VERSION ""

NS_ :

BS_:

BU_: UNKNOWN

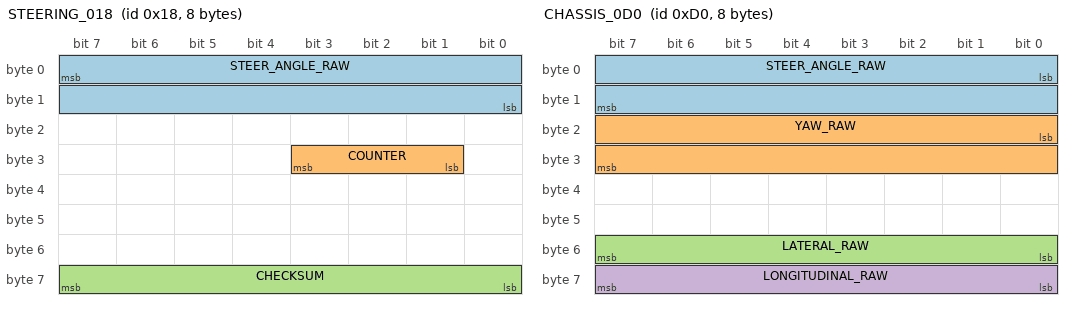
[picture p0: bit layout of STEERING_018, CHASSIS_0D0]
BO_ 24 STEERING_018: 8 UNKNOWN
 SG_ STEER_ANGLE_RAW : 7|16@0- (1,0) [-32768|32767] "raw" UNKNOWN
 SG_ COUNTER : 25|3@1+ (1,0) [0|7] "" UNKNOWN
 SG_ CHECKSUM : 56|8@1+ (1,0) [0|255] "" UNKNOWN

BO_ 208 CHASSIS_0D0: 8 UNKNOWN
 SG_ STEER_ANGLE_RAW : 0|16@1- (1,0) [-32768|32767] "raw" UNKNOWN
 SG_ YAW_RAW : 16|16@1- (1,0) [-32768|32767] "raw" UNKNOWN
 SG_ LATERAL_RAW : 48|8@1- (1,0) [-128|127] "raw" UNKNOWN
 SG_ LONGITUDINAL_RAW : 56|8@1- (1,0) [-128|127] "raw" UNKNOWN

BO_ 209 SPEED_0D1: 4 UNKNOWN
 SG_ VEHICLE_SPEED : 0|16@1+ (0.0563,0) [0|3690] "km/h" UNKNOWN
 SG_ BRAKE_PRESSURE_RAW : 16|8@1+ (1,0) [0|255] "raw" UNKNOWN

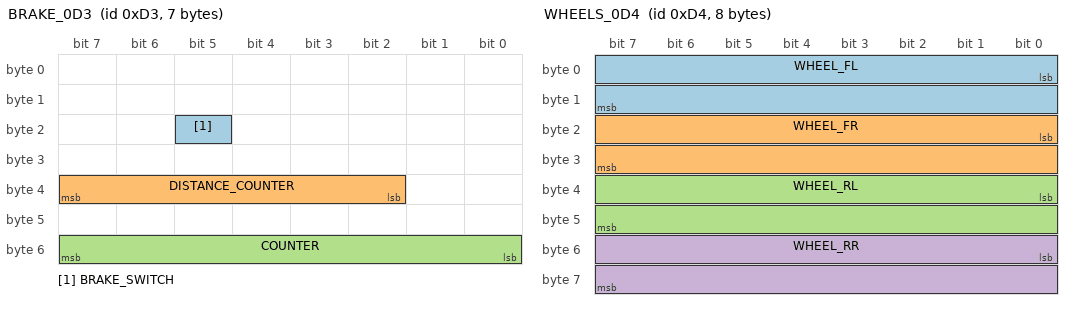
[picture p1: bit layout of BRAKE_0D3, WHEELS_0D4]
BO_ 211 BRAKE_0D3: 7 UNKNOWN
 SG_ BRAKE_SWITCH : 21|1@1+ (1,0) [0|1] "" UNKNOWN
 SG_ DISTANCE_COUNTER : 34|6@1+ (1,0) [0|63] "" UNKNOWN
 SG_ COUNTER : 48|8@1+ (1,0) [0|255] "" UNKNOWN

BO_ 212 WHEELS_0D4: 8 UNKNOWN
 SG_ WHEEL_FL : 0|16@1+ (0.0563,0) [0|3690] "km/h" UNKNOWN
 SG_ WHEEL_FR : 16|16@1+ (0.0563,0) [0|3690] "km/h" UNKNOWN
 SG_ WHEEL_RL : 32|16@1+ (0.0563,0) [0|3690] "km/h" UNKNOWN
 SG_ WHEEL_RR : 48|16@1+ (0.0563,0) [0|3690] "km/h" UNKNOWN

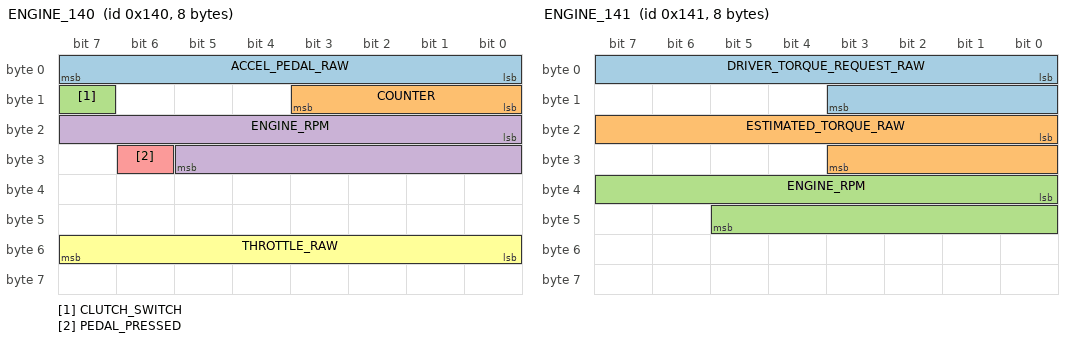
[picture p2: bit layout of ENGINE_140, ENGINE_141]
BO_ 320 ENGINE_140: 8 UNKNOWN
 SG_ ACCEL_PEDAL_RAW : 0|8@1+ (1,0) [0|255] "raw" UNKNOWN
 SG_ COUNTER : 8|4@1+ (1,0) [0|15] "" UNKNOWN
 SG_ CLUTCH_SWITCH : 15|1@1+ (1,0) [0|1] "" UNKNOWN
 SG_ ENGINE_RPM : 16|14@1+ (1,0) [0|16383] "rpm" UNKNOWN
 SG_ PEDAL_PRESSED : 30|1@1+ (1,0) [0|1] "" UNKNOWN
 SG_ THROTTLE_RAW : 48|8@1+ (1,0) [0|255] "raw" UNKNOWN

BO_ 321 ENGINE_141: 8 UNKNOWN
 SG_ DRIVER_TORQUE_REQUEST_RAW : 0|12@1+ (1,0) [0|4095] "raw" UNKNOWN
 SG_ ESTIMATED_TORQUE_RAW : 16|12@1+ (1,0) [0|4095] "raw" UNKNOWN
 SG_ ENGINE_RPM : 32|14@1+ (1,0) [0|16383] "rpm" UNKNOWN

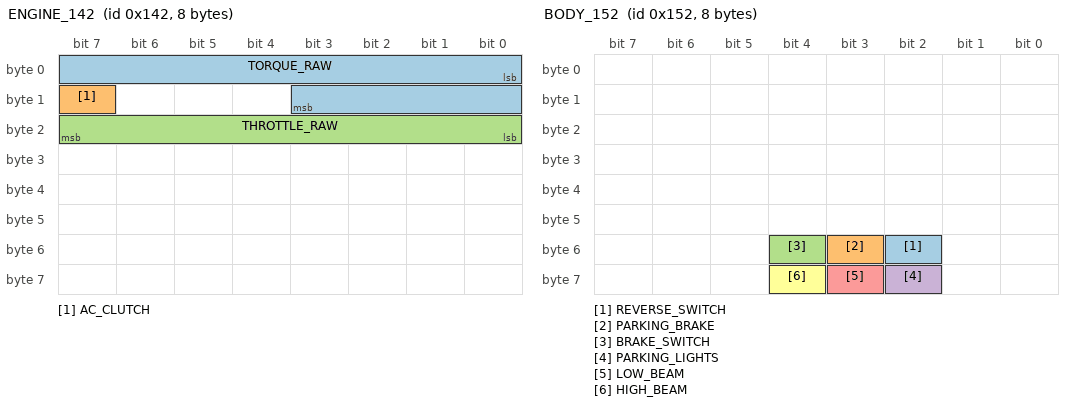
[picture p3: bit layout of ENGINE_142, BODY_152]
BO_ 322 ENGINE_142: 8 UNKNOWN
 SG_ TORQUE_RAW : 0|12@1+ (1,0) [0|4095] "raw" UNKNOWN
 SG_ AC_CLUTCH : 15|1@1+ (1,0) [0|1] "" UNKNOWN
 SG_ THROTTLE_RAW : 16|8@1+ (1,0) [0|255] "raw" UNKNOWN

BO_ 338 BODY_152: 8 UNKNOWN
 SG_ REVERSE_SWITCH : 50|1@1+ (1,0) [0|1] "" UNKNOWN
 SG_ PARKING_BRAKE : 51|1@1+ (1,0) [0|1] "" UNKNOWN
 SG_ BRAKE_SWITCH : 52|1@1+ (1,0) [0|1] "" UNKNOWN
 SG_ PARKING_LIGHTS : 58|1@1+ (1,0) [0|1] "" UNKNOWN
 SG_ LOW_BEAM : 59|1@1+ (1,0) [0|1] "" UNKNOWN
 SG_ HIGH_BEAM : 60|1@1+ (1,0) [0|1] "" UNKNOWN

BO_ 640 STATUS_280: 8 UNKNOWN
 SG_ AC_REQUEST : 0|1@1+ (1,0) [0|1] "" UNKNOWN

BO_ 642 BODY_282: 8 UNKNOWN
 SG_ SEATBELT_UNBUCKLED : 40|1@1+ (1,0) [0|1] "" UNKNOWN

BO_ 644 START_284: 8 UNKNOWN
 SG_ CLUTCH_START_INTERLOCK : 44|1@1+ (1,0) [0|1] "" UNKNOWN

BO_ 864 ENGINE_360: 8 UNKNOWN
 SG_ OIL_TEMP : 16|8@1+ (1,-40) [-40|215] "C" UNKNOWN
 SG_ COOLANT_TEMP : 24|8@1+ (1,-40) [-40|215] "C" UNKNOWN

BO_ 865 ENGINE_361: 8 UNKNOWN
 SG_ ENGINE_RUNNING_LIKELY : 13|1@1+ (1,0) [0|1] "" UNKNOWN

BO_ 884 BODY_374: 8 UNKNOWN
 SG_ DOOR_OPEN : 24|1@1+ (1,0) [0|1] "" UNKNOWN

BO_ 885 BODY_375: 8 UNKNOWN
 SG_ DOOR_UNLOCKED : 0|2@1+ (1,0) [0|3] "" UNKNOWN

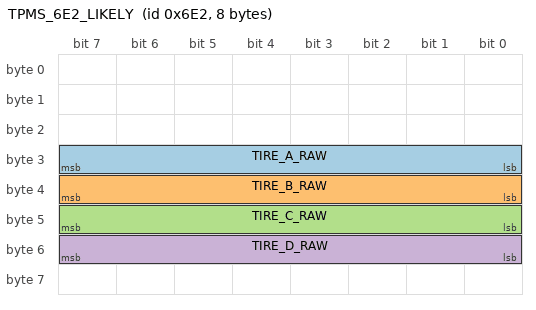
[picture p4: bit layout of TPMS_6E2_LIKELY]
BO_ 1762 TPMS_6E2_LIKELY: 8 UNKNOWN
 SG_ TIRE_A_RAW : 24|8@1+ (1,0) [0|255] "raw" UNKNOWN
 SG_ TIRE_B_RAW : 32|8@1+ (1,0) [0|255] "raw" UNKNOWN
 SG_ TIRE_C_RAW : 40|8@1+ (1,0) [0|255] "raw" UNKNOWN
 SG_ TIRE_D_RAW : 48|8@1+ (1,0) [0|255] "raw" UNKNOWN

CM_ SG_ 209 VEHICLE_SPEED "Scale from the Link ECU RPM/kph channel. An unloaded 245/40R17 tire with the 4.30 final drive gives 0.0578. Not compared with GPS.";
